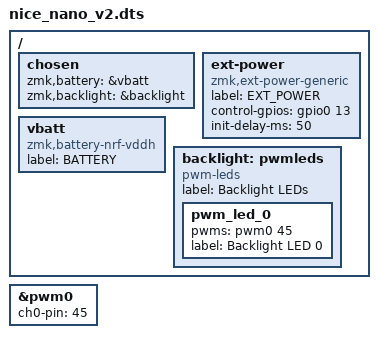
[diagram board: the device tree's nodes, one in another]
/*
 * Copyright (c) 2021 The ZMK Contributors
 *
 * SPDX-License-Identifier: MIT
 */

/dts-v1/;
#include "nice_nano.dtsi"

/ {
    chosen {
        zmk,battery = &vbatt;
        zmk,backlight = &backlight;
    };

    ext-power {
        compatible = "zmk,ext-power-generic";
        label = "EXT_POWER";
        control-gpios = <&gpio0 13 GPIO_ACTIVE_HIGH>;
        init-delay-ms = <50>;
    };

    vbatt: vbatt {
        compatible = "zmk,battery-nrf-vddh";
        label = "BATTERY";
    };

    backlight: pwmleds {
        compatible = "pwm-leds";
        label = "Backlight LEDs";
        pwm_led_0 {
            pwms = <&pwm0 45>;
            label = "Backlight LED 0";
        };
    };
};

&pwm0 {
    status = "okay";
    ch0-pin = <45>;
    /* ch0-inverted; */
};
